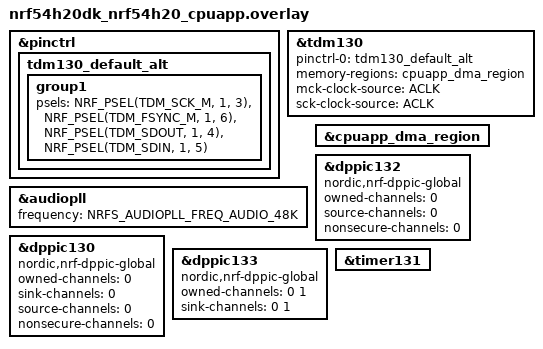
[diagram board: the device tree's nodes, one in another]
/*
 * Copyright (c) 2025 Nordic Semiconductor ASA
 *
 * SPDX-License-Identifier: Apache-2.0
 */

#include "../app.overlay"

&pinctrl {
	tdm130_default_alt: tdm130_default_alt {
		group1 {
			psels = <NRF_PSEL(TDM_SCK_M, 1, 3)>,
				<NRF_PSEL(TDM_FSYNC_M, 1, 6)>,
				<NRF_PSEL(TDM_SDOUT, 1, 4)>,
				<NRF_PSEL(TDM_SDIN, 1, 5)>;
		};
	};
};

i2s_rxtx: &tdm130 {
	status = "okay";
	pinctrl-0 = <&tdm130_default_alt>;
	pinctrl-names = "default";
	memory-regions = <&cpuapp_dma_region>;
	mck-clock-source = "ACLK";
	sck-clock-source = "ACLK";
};

&audiopll {
	frequency = <NRFS_AUDIOPLL_FREQ_AUDIO_48K>;
	status = "okay";
};

&cpuapp_dma_region {
	status = "okay";
};

/* PPI channel 0 for TDM130 MAXCNT */
&dppic132 {
	compatible = "nordic,nrf-dppic-global";
	owned-channels = <0>;
	source-channels = <0>;
	nonsecure-channels = <0>;
	status = "okay";
};

/* TDM130 PPI needs routing to TIMER131 through main APB */
&dppic130 {
	compatible = "nordic,nrf-dppic-global";
	owned-channels = <0>;
	sink-channels = <0>;
	source-channels = <0>;
	nonsecure-channels = <0>;
	status = "okay";
};

/* TIMER131 PPI channel 1 is used for SOF */
&dppic133 {
	compatible = "nordic,nrf-dppic-global";
	owned-channels = <0 1>;
	sink-channels = <0 1>;
	status = "okay";
};

&timer131 {
	status = "okay";
};
